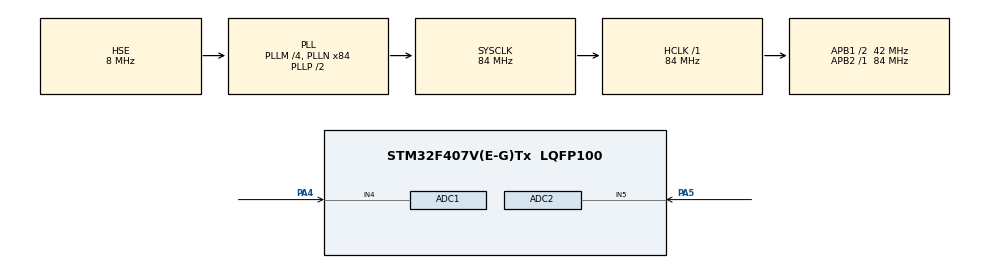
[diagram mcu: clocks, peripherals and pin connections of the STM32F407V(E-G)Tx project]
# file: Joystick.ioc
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ADC1.Channel-1\#ChannelRegularConversion=ADC_CHANNEL_4
ADC1.NbrOfConversion=1
ADC1.NbrOfConversionFlag=1
ADC1.Rank-1\#ChannelRegularConversion=1
ADC1.SamplingTime-1\#ChannelRegularConversion=ADC_SAMPLETIME_480CYCLES
ADC1.master=1
ADC2.Channel-1\#ChannelRegularConversion=ADC_CHANNEL_5
ADC2.NbrOfConversionFlag=1
ADC2.Rank-1\#ChannelRegularConversion=1
ADC2.SamplingTime-1\#ChannelRegularConversion=ADC_SAMPLETIME_480CYCLES
Mcu.Family=STM32F4
Mcu.Name=STM32F407V(E-G)Tx
Mcu.Package=LQFP100
NVIC.PriorityGroup=NVIC_PRIORITYGROUP_0
PA13.Mode=Trace_Asynchronous_SW
PA13.Signal=SYS_JTMS-SWDIO
PA14.Mode=Trace_Asynchronous_SW
PA14.Signal=SYS_JTCK-SWCLK
PA4.Signal=ADCx_IN4
PA5.Signal=ADCx_IN5
PB3.Mode=Trace_Asynchronous_SW
PB3.Signal=SYS_JTDO-SWO
PH0-OSC_IN.Mode=HSE-External-Clock-Source
PH0-OSC_IN.Signal=RCC_OSC_IN
PH1-OSC_OUT.Mode=HSE-External-Clock-Source
PH1-OSC_OUT.Signal=RCC_OSC_OUT
ProjectManager.HeapSize=0x200
ProjectManager.StackSize=0x400
ProjectManager.TargetToolchain=STM32CubeIDE
RCC.48MHZClocksFreq_Value=24000000
RCC.AHBFreq_Value=84000000
RCC.APB1CLKDivider=RCC_HCLK_DIV2
RCC.APB1Freq_Value=42000000
RCC.APB1TimFreq_Value=84000000
RCC.APB2Freq_Value=84000000
RCC.APB2TimFreq_Value=84000000
RCC.CortexFreq_Value=84000000
RCC.HCLKFreq_Value=84000000
RCC.HSE_VALUE=8000000
RCC.HSI_VALUE=16000000
RCC.PLLM=4
RCC.PLLN=84
RCC.PLLQ=7
RCC.PLLSourceVirtual=RCC_PLLSOURCE_HSE
RCC.SYSCLKFreq_VALUE=84000000
RCC.SYSCLKSource=RCC_SYSCLKSOURCE_PLLCLK
RCC.VCOOutputFreq_Value=168000000
SH.ADCx_IN4.0=ADC1_IN4,IN4
SH.ADCx_IN5.0=ADC2_IN5,IN5
board=STM32F407G-DISC1

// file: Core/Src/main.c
/* USER CODE BEGIN Header */
/**
  ******************************************************************************
  * @file           : main.c
  * @brief          : Main program body
  ******************************************************************************
  * @attention
  *
  * Copyright (c) 2023 STMicroelectronics.
  * All rights reserved.
  *
  * This software is licensed under terms that can be found in the LICENSE file
  * in the root directory of this software component.
  * If no LICENSE file comes with this software, it is provided AS-IS.
  *
  ******************************************************************************
  */
/* USER CODE END Header */
#include "main.h"

ADC_HandleTypeDef hadc1;
ADC_HandleTypeDef hadc2;

/* USER CODE BEGIN PV */
uint16_t adc1_value;
uint16_t adc2_value;
/* USER CODE END PV */

void SystemClock_Config(void);
static void MX_GPIO_Init(void);
static void MX_ADC1_Init(void);
static void MX_ADC2_Init(void);

int main(void)
{

  /* MCU Configuration--------------------------------------------------------*/

  /* Reset of all peripherals, Initializes the Flash interface and the Systick. */
  HAL_Init();

  /* Configure the system clock */
  SystemClock_Config();

  /* Initialize all configured peripherals */
  MX_GPIO_Init();
  MX_ADC1_Init();
  MX_ADC2_Init();

  /* Infinite loop */
  /* USER CODE BEGIN WHILE */
  while (1)
  {

	  if (HAL_ADC_Start(&hadc1) != HAL_OK){
		  Error_Handler();
	  }
	  if (HAL_ADC_Start(&hadc2) != HAL_OK){
		  Error_Handler();
	  }

	  if (HAL_ADC_PollForConversion(&hadc1, 20) != HAL_OK){
		  Error_Handler();
	  }
	  if (HAL_ADC_PollForConversion(&hadc2, 20) != HAL_OK){
		  Error_Handler();
	  }

	  adc1_value = HAL_ADC_GetValue(&hadc1);
	  adc2_value = HAL_ADC_GetValue(&hadc2);
    /* USER CODE END WHILE */

  }
}

void SystemClock_Config(void)
{
  RCC_OscInitTypeDef RCC_OscInitStruct = {0};
  RCC_ClkInitTypeDef RCC_ClkInitStruct = {0};

  /** Configure the main internal regulator output voltage
  */
  __HAL_RCC_PWR_CLK_ENABLE();
  __HAL_PWR_VOLTAGESCALING_CONFIG(PWR_REGULATOR_VOLTAGE_SCALE1);

  /** Initializes the RCC Oscillators according to the specified parameters
  * in the RCC_OscInitTypeDef structure.
  */
  RCC_OscInitStruct.OscillatorType = RCC_OSCILLATORTYPE_HSE;
  RCC_OscInitStruct.HSEState = RCC_HSE_BYPASS;
  RCC_OscInitStruct.PLL.PLLState = RCC_PLL_ON;
  RCC_OscInitStruct.PLL.PLLSource = RCC_PLLSOURCE_HSE;
  RCC_OscInitStruct.PLL.PLLM = 4;
  RCC_OscInitStruct.PLL.PLLN = 84;
  RCC_OscInitStruct.PLL.PLLP = RCC_PLLP_DIV2;
  RCC_OscInitStruct.PLL.PLLQ = 7;
  if (HAL_RCC_OscConfig(&RCC_OscInitStruct) != HAL_OK)
  {
    Error_Handler();
  }

  /** Initializes the CPU, AHB and APB buses clocks
  */
  RCC_ClkInitStruct.ClockType = RCC_CLOCKTYPE_HCLK|RCC_CLOCKTYPE_SYSCLK
                              |RCC_CLOCKTYPE_PCLK1|RCC_CLOCKTYPE_PCLK2;
  RCC_ClkInitStruct.SYSCLKSource = RCC_SYSCLKSOURCE_PLLCLK;
  RCC_ClkInitStruct.AHBCLKDivider = RCC_SYSCLK_DIV1;
  RCC_ClkInitStruct.APB1CLKDivider = RCC_HCLK_DIV2;
  RCC_ClkInitStruct.APB2CLKDivider = RCC_HCLK_DIV1;

  if (HAL_RCC_ClockConfig(&RCC_ClkInitStruct, FLASH_LATENCY_2) != HAL_OK)
  {
    Error_Handler();
  }
}

static void MX_ADC1_Init(void)
{

  ADC_ChannelConfTypeDef sConfig = {0};

  /** Configure the global features of the ADC (Clock, Resolution, Data Alignment and number of conversion)
  */
  hadc1.Instance = ADC1;
  hadc1.Init.ClockPrescaler = ADC_CLOCK_SYNC_PCLK_DIV4;
  hadc1.Init.Resolution = ADC_RESOLUTION_12B;
  hadc1.Init.ScanConvMode = DISABLE;
  hadc1.Init.ContinuousConvMode = DISABLE;
  hadc1.Init.DiscontinuousConvMode = DISABLE;
  hadc1.Init.ExternalTrigConvEdge = ADC_EXTERNALTRIGCONVEDGE_NONE;
  hadc1.Init.ExternalTrigConv = ADC_SOFTWARE_START;
  hadc1.Init.DataAlign = ADC_DATAALIGN_RIGHT;
  hadc1.Init.NbrOfConversion = 1;
  hadc1.Init.DMAContinuousRequests = DISABLE;
  hadc1.Init.EOCSelection = ADC_EOC_SINGLE_CONV;
  if (HAL_ADC_Init(&hadc1) != HAL_OK)
  {
    Error_Handler();
  }

  /** Configure for the selected ADC regular channel its corresponding rank in the sequencer and its sample time.
  */
  sConfig.Channel = ADC_CHANNEL_4;
  sConfig.Rank = 1;
  sConfig.SamplingTime = ADC_SAMPLETIME_480CYCLES;
  if (HAL_ADC_ConfigChannel(&hadc1, &sConfig) != HAL_OK)
  {
    Error_Handler();
  }

}

static void MX_ADC2_Init(void)
{

  ADC_ChannelConfTypeDef sConfig = {0};

  /** Configure the global features of the ADC (Clock, Resolution, Data Alignment and number of conversion)
  */
  hadc2.Instance = ADC2;
  hadc2.Init.ClockPrescaler = ADC_CLOCK_SYNC_PCLK_DIV4;
  hadc2.Init.Resolution = ADC_RESOLUTION_12B;
  hadc2.Init.ScanConvMode = DISABLE;
  hadc2.Init.ContinuousConvMode = DISABLE;
  hadc2.Init.DiscontinuousConvMode = DISABLE;
  hadc2.Init.ExternalTrigConvEdge = ADC_EXTERNALTRIGCONVEDGE_NONE;
  hadc2.Init.ExternalTrigConv = ADC_SOFTWARE_START;
  hadc2.Init.DataAlign = ADC_DATAALIGN_RIGHT;
  hadc2.Init.NbrOfConversion = 1;
  hadc2.Init.DMAContinuousRequests = DISABLE;
  hadc2.Init.EOCSelection = ADC_EOC_SINGLE_CONV;
  if (HAL_ADC_Init(&hadc2) != HAL_OK)
  {
    Error_Handler();
  }

  /** Configure for the selected ADC regular channel its corresponding rank in the sequencer and its sample time.
  */
  sConfig.Channel = ADC_CHANNEL_5;
  sConfig.Rank = 1;
  sConfig.SamplingTime = ADC_SAMPLETIME_480CYCLES;
  if (HAL_ADC_ConfigChannel(&hadc2, &sConfig) != HAL_OK)
  {
    Error_Handler();
  }

}

static void MX_GPIO_Init(void)
{

  /* GPIO Ports Clock Enable */
  __HAL_RCC_GPIOH_CLK_ENABLE();
  __HAL_RCC_GPIOA_CLK_ENABLE();
  __HAL_RCC_GPIOB_CLK_ENABLE();

}

void Error_Handler(void)
{
  __disable_irq();
  while (1)
  {
  }
}
